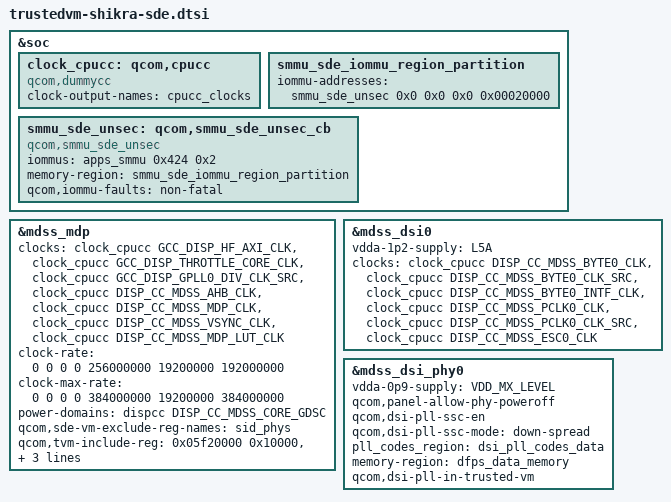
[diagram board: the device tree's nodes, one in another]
// SPDX-License-Identifier: BSD-3-Clause
/*
 * Copyright (c) Qualcomm Technologies, Inc. and/or its subsidiaries.
 */

#include <dt-bindings/clock/qcom,shikra-gcc.h>
#include <dt-bindings/clock/qcom,shikra-dispcc.h>
#include <dt-bindings/interconnect/qcom,shikra.h>

#include "shikra-sde-common.dtsi"

&soc {
	/* dummy display clock provider */
	clock_cpucc: qcom,cpucc {
		compatible = "qcom,dummycc";
		clock-output-names = "cpucc_clocks";
		#clock-cells = <1>;
	};

	smmu_sde_iommu_region_partition: smmu_sde_iommu_region_partition {
		iommu-addresses = <&smmu_sde_unsec 0x0 0x0 0x0 0x00020000>;
	};

	smmu_sde_unsec: qcom,smmu_sde_unsec_cb {
		compatible = "qcom,smmu_sde_unsec";
		iommus = <&apps_smmu 0x424 0x2>;
		memory-region = <&smmu_sde_iommu_region_partition>;
		qcom,iommu-faults = "non-fatal";
	};
};

&mdss_mdp {
		clocks =
			<&clock_cpucc GCC_DISP_HF_AXI_CLK>,
			<&clock_cpucc GCC_DISP_THROTTLE_CORE_CLK>,
			<&clock_cpucc GCC_DISP_GPLL0_DIV_CLK_SRC>,
			<&clock_cpucc DISP_CC_MDSS_AHB_CLK>,
			<&clock_cpucc DISP_CC_MDSS_MDP_CLK>,
			<&clock_cpucc DISP_CC_MDSS_VSYNC_CLK>,
			<&clock_cpucc DISP_CC_MDSS_MDP_LUT_CLK>;
		clock-names = "gcc_bus", "throttle_clk", "div_clk",
				"iface_clk", "core_clk", "vsync_clk",
				"lut_clk";
		clock-rate = <0 0 0 0 256000000 19200000 192000000>;
		clock-max-rate = <0 0 0 0 384000000 19200000 384000000>;

		power-domains = <&dispcc DISP_CC_MDSS_CORE_GDSC>;

		qcom,sde-vm-exclude-reg-names = "sid_phys";
		qcom,tvm-include-reg = <0x05f20000 0x10000>,
					<0x5f30000 0x100>,
					<0x5f31000 0x100>,
					<0x5f32000 0x100>,
					<0x5f33000 0x100>;
		qcom,sde-trusted-vm-env;
};

&mdss_dsi0 {
	vdda-1p2-supply = <&L5A>;
	clocks =
		<&clock_cpucc DISP_CC_MDSS_BYTE0_CLK>,
		<&clock_cpucc DISP_CC_MDSS_BYTE0_CLK_SRC>,
		<&clock_cpucc DISP_CC_MDSS_BYTE0_INTF_CLK>,
		<&clock_cpucc DISP_CC_MDSS_PCLK0_CLK>,
		<&clock_cpucc DISP_CC_MDSS_PCLK0_CLK_SRC>,
		<&clock_cpucc DISP_CC_MDSS_ESC0_CLK>;
	clock-names = "byte_clk", "byte_clk_rcg", "byte_intf_clk",
			"pixel_clk", "pixel_clk_rcg", "esc_clk";
};

&mdss_dsi_phy0 {
	vdda-0p9-supply = <&VDD_MX_LEVEL>;
	qcom,panel-allow-phy-poweroff;
	qcom,dsi-pll-ssc-en;
	qcom,dsi-pll-ssc-mode = "down-spread";
	pll_codes_region = <&dsi_pll_codes_data>;
	memory-region = <&dfps_data_memory>;
	qcom,dsi-pll-in-trusted-vm;
};
